AUTOSAR XML (schema 00046)
package /Runnable_behavior
  sender receiver interface SR_IF_internal_Behavior
    data CDM: type=uint32
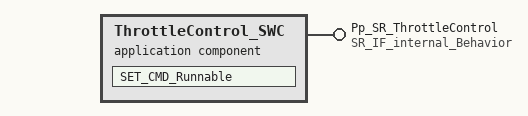
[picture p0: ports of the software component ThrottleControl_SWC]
  application sw component type ThrottleControl_SWC
    provide port Pp_SR_ThrottleControl: provided-interface=SR_IF_internal_Behavior
    behavior ThrottleControl_Behavior
      runnable SET_CMD_Runnable: symbol=Set_CMD
        data-write-access:
          access Data_CMD: accessed-variable=Pp_SR_ThrottleControl.CDM
